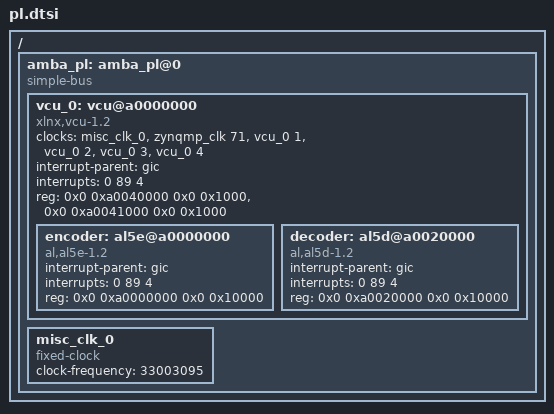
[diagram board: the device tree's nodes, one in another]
/*
 * CAUTION: This file is automatically generated by Xilinx.
 * Version:  
 * Today is: Fri May 31 07:39:59 2024
 */


/ {
	amba_pl: amba_pl@0 {
		#address-cells = <2>;
		#size-cells = <2>;
		compatible = "simple-bus";
		ranges ;
		vcu_0: vcu@a0000000 {
			#address-cells = <2>;
			#clock-cells = <1>;
			#size-cells = <2>;
			clock-names = "pll_ref", "aclk", "vcu_core_enc", "vcu_core_dec", "vcu_mcu_enc", "vcu_mcu_dec";
			clocks = <&misc_clk_0>, <&zynqmp_clk 71>, <&vcu_0 1>, <&vcu_0 2>, <&vcu_0 3>, <&vcu_0 4>;
			compatible = "xlnx,vcu-1.2", "xlnx,vcu";
			interrupt-names = "vcu_host_interrupt";
			interrupt-parent = <&gic>;
			interrupts = <0 89 4>;
			ranges ;
			reg = <0x0 0xa0040000 0x0 0x1000>, <0x0 0xa0041000 0x0 0x1000>;
			reg-names = "vcu_slcr", "logicore";
			encoder: al5e@a0000000 {
				compatible = "al,al5e-1.2", "al,al5e";
				interrupt-parent = <&gic>;
				interrupts = <0 89 4>;
				reg = <0x0 0xa0000000 0x0 0x10000>;
			};
			decoder: al5d@a0020000 {
				compatible = "al,al5d-1.2", "al,al5d";
				interrupt-parent = <&gic>;
				interrupts = <0 89 4>;
				reg = <0x0 0xa0020000 0x0 0x10000>;
			};
		};
		misc_clk_0: misc_clk_0 {
			#clock-cells = <0>;
			clock-frequency = <33003095>;
			compatible = "fixed-clock";
		};
	};
};
